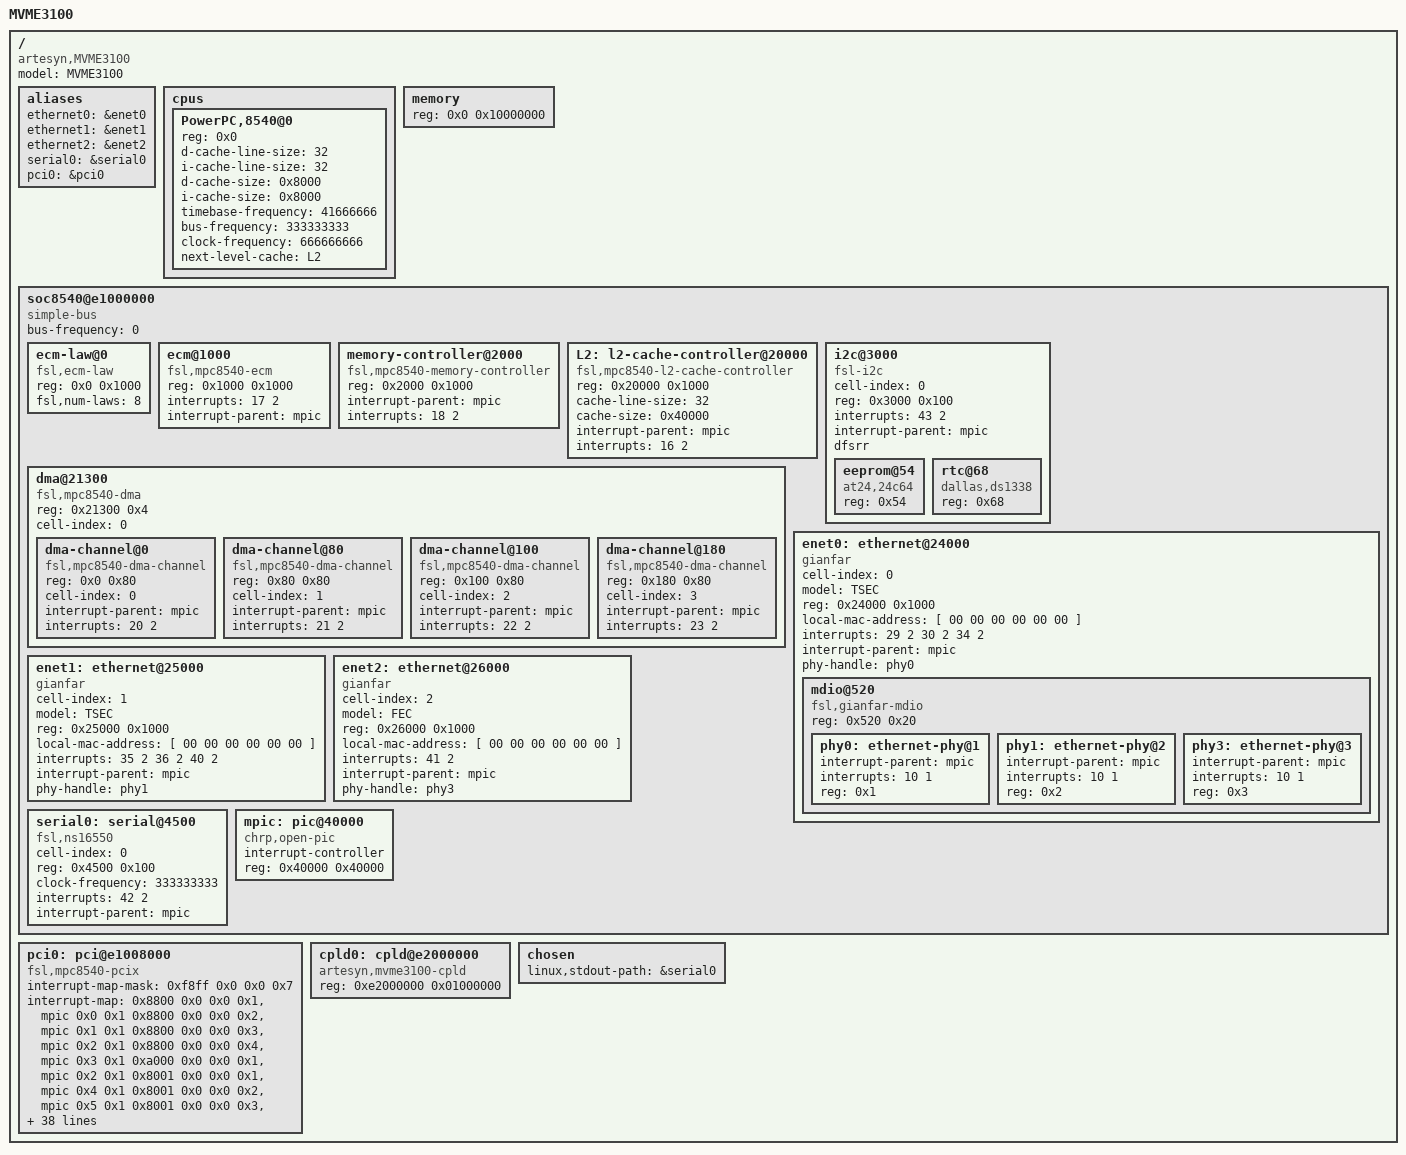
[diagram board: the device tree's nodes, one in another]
/*
 * MVME3100 Device Tree Source
 *
 * Copyright 2017 Michael Davidsaver
 * Copyright 2006, 2008 Freescale Semiconductor Inc.
 *
 * This program is free software; you can redistribute  it and/or modify it
 * under  the terms of  the GNU General  Public License as published by the
 * Free Software Foundation;  either version 2 of the  License, or (at your
 * option) any later version.
 */

/dts-v1/;

/include/ "e500v2_power_isa.dtsi"

/ {
        model = "MVME3100";
        compatible = "artesyn,MVME3100", "MPC85xxADS";
	#address-cells = <1>;
	#size-cells = <1>;

	aliases {
		ethernet0 = &enet0;
		ethernet1 = &enet1;
		ethernet2 = &enet2;
		serial0 = &serial0;
		pci0 = &pci0;
	};

	cpus {
		#address-cells = <1>;
		#size-cells = <0>;

		PowerPC,8540@0 {
			device_type = "cpu";
			reg = <0x0>;
			d-cache-line-size = <32>;	// 32 bytes
			i-cache-line-size = <32>;	// 32 bytes
			d-cache-size = <0x8000>;		// L1, 32K
			i-cache-size = <0x8000>;		// L1, 32K
			timebase-frequency = <41666666>;	//  CCB/8
			bus-frequency = <333333333>;	// CCB
			clock-frequency = <666666666>;	// core for mvme3100-1152
			next-level-cache = <&L2>;
		};
	};

	memory {
		device_type = "memory";
		reg = <0x0 0x10000000>;	// 256M at 0x0
	};

	soc8540@e1000000 {
		#address-cells = <1>;
		#size-cells = <1>;
		device_type = "soc";
		compatible = "simple-bus";
		ranges = <0x0 0xe1000000 0x100000>;
		bus-frequency = <0>;

		ecm-law@0 {
			compatible = "fsl,ecm-law";
			reg = <0x0 0x1000>;
			fsl,num-laws = <8>;
		};

		ecm@1000 {
			compatible = "fsl,mpc8540-ecm", "fsl,ecm";
			reg = <0x1000 0x1000>;
			interrupts = <17 2>;
			interrupt-parent = <&mpic>;
		};

		memory-controller@2000 {
			compatible = "fsl,mpc8540-memory-controller";
			reg = <0x2000 0x1000>;
			interrupt-parent = <&mpic>;
			interrupts = <18 2>;
		};

		L2: l2-cache-controller@20000 {
			compatible = "fsl,mpc8540-l2-cache-controller";
			reg = <0x20000 0x1000>;
			cache-line-size = <32>;	// 32 bytes
			cache-size = <0x40000>;	// L2, 256K
			interrupt-parent = <&mpic>;
			interrupts = <16 2>;
		};

		i2c@3000 {
			#address-cells = <1>;
			#size-cells = <0>;
			cell-index = <0>;
			compatible = "fsl-i2c";
			reg = <0x3000 0x100>;
			interrupts = <43 2>;
			interrupt-parent = <&mpic>;
			dfsrr;

			eeprom@54 {
				compatible = "at24,24c64";
				reg = <0x54>;
			};

                        rtc@68 {
                                compatible = "dallas,ds1338";
                                reg = <0x68>;
                        };
		};

		dma@21300 {
			#address-cells = <1>;
			#size-cells = <1>;
			compatible = "fsl,mpc8540-dma", "fsl,eloplus-dma";
			reg = <0x21300 0x4>;
			ranges = <0x0 0x21100 0x200>;
			cell-index = <0>;
			dma-channel@0 {
				compatible = "fsl,mpc8540-dma-channel",
						"fsl,eloplus-dma-channel";
				reg = <0x0 0x80>;
				cell-index = <0>;
				interrupt-parent = <&mpic>;
				interrupts = <20 2>;
			};
			dma-channel@80 {
				compatible = "fsl,mpc8540-dma-channel",
						"fsl,eloplus-dma-channel";
				reg = <0x80 0x80>;
				cell-index = <1>;
				interrupt-parent = <&mpic>;
				interrupts = <21 2>;
			};
			dma-channel@100 {
				compatible = "fsl,mpc8540-dma-channel",
						"fsl,eloplus-dma-channel";
				reg = <0x100 0x80>;
				cell-index = <2>;
				interrupt-parent = <&mpic>;
				interrupts = <22 2>;
			};
			dma-channel@180 {
				compatible = "fsl,mpc8540-dma-channel",
						"fsl,eloplus-dma-channel";
				reg = <0x180 0x80>;
				cell-index = <3>;
				interrupt-parent = <&mpic>;
				interrupts = <23 2>;
			};
		};

		/* GMII */
		enet0: ethernet@24000 {
			#address-cells = <1>;
			#size-cells = <1>;
			cell-index = <0>;
			device_type = "network";
			model = "TSEC";
			compatible = "gianfar";
			reg = <0x24000 0x1000>;
			ranges = <0x0 0x24000 0x1000>;
			local-mac-address = [ 00 00 00 00 00 00 ];
			interrupts = <29 2 30 2 34 2>;
			interrupt-parent = <&mpic>;
			phy-handle = <&phy0>;

			mdio@520 {
				#address-cells = <1>;
				#size-cells = <0>;
				compatible = "fsl,gianfar-mdio";
				reg = <0x520 0x20>;

				phy0: ethernet-phy@1 {
					interrupt-parent = <&mpic>;
					interrupts = <10 1>;
					reg = <0x1>;
				};
				phy1: ethernet-phy@2 {
					interrupt-parent = <&mpic>;
					interrupts = <10 1>;
					reg = <0x2>;
				};
				phy3: ethernet-phy@3 {
					interrupt-parent = <&mpic>;
					interrupts = <10 1>;
					reg = <0x3>;
				};
			};
		};

		/* GMII */
		enet1: ethernet@25000 {
			#address-cells = <1>;
			#size-cells = <1>;
			cell-index = <1>;
			device_type = "network";
			model = "TSEC";
			compatible = "gianfar";
			reg = <0x25000 0x1000>;
			ranges = <0x0 0x25000 0x1000>;
			local-mac-address = [ 00 00 00 00 00 00 ];
			interrupts = <35 2 36 2 40 2>;
			interrupt-parent = <&mpic>;
			phy-handle = <&phy1>;
		};

		/* TODO: actually a 10/100 FEC interface */
		enet2: ethernet@26000 {
			#address-cells = <1>;
			#size-cells = <1>;
			cell-index = <2>;
			device_type = "network";
			model = "FEC";
			compatible = "gianfar";
			reg = <0x26000 0x1000>;
			ranges = <0x0 0x26000 0x1000>;
			local-mac-address = [ 00 00 00 00 00 00 ];
			interrupts = <41 2>;
			interrupt-parent = <&mpic>;
			phy-handle = <&phy3>;
		};

		serial0: serial@4500 {
			cell-index = <0>;
			device_type = "serial";
			compatible = "fsl,ns16550", "ns16550";
			reg = <0x4500 0x100>; 	// reg base, size
                        clock-frequency = <333333333>;  // CCB
			interrupts = <42 2>;
			interrupt-parent = <&mpic>;
		};

		mpic: pic@40000 {
			interrupt-controller;
			#address-cells = <0>;
			#interrupt-cells = <2>;
			reg = <0x40000 0x40000>;
			compatible = "chrp,open-pic";
			device_type = "open-pic";
		};
	};

	pci0: pci@e1008000 {
		interrupt-map-mask = <0xf8ff 0x0 0x0 0x7>;
		interrupt-map = <

		/* On Host bridge (bus 0) */

		/* IDSEL 17 (TSI148) */
		0x8800 0x0 0x0 0x1 &mpic 0x0 0x1
		0x8800 0x0 0x0 0x2 &mpic 0x1 0x1
		0x8800 0x0 0x0 0x3 &mpic 0x2 0x1
		0x8800 0x0 0x0 0x4 &mpic 0x3 0x1

		/* IDSEL 20 (SATA) */
		0xa000 0x0 0x0 0x1 &mpic 0x2 0x1

		/* behind bridge 0:12.0 (bus 1) */

		/* IDSEL 16 (PMC1 pri) */
		0x8001 0x0 0x0 0x1 &mpic 0x4 0x1
		0x8001 0x0 0x0 0x2 &mpic 0x5 0x1
		0x8001 0x0 0x0 0x3 &mpic 0x6 0x1
		0x8001 0x0 0x0 0x4 &mpic 0x7 0x1

		/* IDSEL 17 (PMC1 sec */
		0x8801 0x0 0x0 0x1 &mpic 0x5 0x1
		0x8801 0x0 0x0 0x2 &mpic 0x6 0x1
		0x8801 0x0 0x0 0x3 &mpic 0x7 0x1
		0x8001 0x0 0x0 0x4 &mpic 0x4 0x1

		/* IDSEL 18 (PMC2 pri) */
		0x9001 0x0 0x0 0x1 &mpic 0x6 0x1
		0x9001 0x0 0x0 0x2 &mpic 0x7 0x1
		0x9001 0x0 0x0 0x3 &mpic 0x4 0x1
		0x9001 0x0 0x0 0x4 &mpic 0x5 0x1

		/* IDSEL 19 (PMC2 sec */
		0x9801 0x0 0x0 0x1 &mpic 0x7 0x1
		0x9801 0x0 0x0 0x2 &mpic 0x4 0x1
		0x9801 0x0 0x0 0x3 &mpic 0x5 0x1
		0x9001 0x0 0x0 0x4 &mpic 0x6 0x1

		/* behind bridge 0:13.0 (bus 2) */

		/* IDSEL 16 (USB) */
		0x8002 0x0 0x0 0x1 &mpic 0x4 0x1
		0x8002 0x0 0x0 0x2 &mpic 0x5 0x1
		0x8002 0x0 0x0 0x3 &mpic 0x6 0x1

		/* IDSEL 18 (PMCSpan slot 1) */
		0x9002 0x0 0x0 0x1 &mpic 0x6 0x1
		0x9002 0x0 0x0 0x2 &mpic 0x7 0x1
		0x9002 0x0 0x0 0x3 &mpic 0x4 0x1
		0x9002 0x0 0x0 0x4 &mpic 0x5 0x1

		/* IDSEL 19 (PMCSpan slot 2) */
		0x9802 0x0 0x0 0x1 &mpic 0x7 0x1
		0x9802 0x0 0x0 0x2 &mpic 0x4 0x1
		0x9802 0x0 0x0 0x3 &mpic 0x5 0x1
		0x9002 0x0 0x0 0x4 &mpic 0x6 0x1

		/* IDSEL 20 (PMCSpan slot 3) */
		0xa002 0x0 0x0 0x1 &mpic 0x4 0x1
		0xa002 0x0 0x0 0x2 &mpic 0x5 0x1
		0xa002 0x0 0x0 0x3 &mpic 0x6 0x1
		0xa002 0x0 0x0 0x4 &mpic 0x7 0x1

		/* IDSEL 21 (PMCSpan slot 4) */
		0xa802 0x0 0x0 0x1 &mpic 0x5 0x1
		0xa802 0x0 0x0 0x2 &mpic 0x6 0x1
		0xa802 0x0 0x0 0x3 &mpic 0x7 0x1
		0xa802 0x0 0x0 0x4 &mpic 0x8 0x1>;

		interrupt-parent = <&mpic>;
		interrupts = <24 2>;
		bus-range = <0 0>;
                ranges = <0x2000000 0x0 0x80000000 0x80000000 0x0 0x40000000
                              0x2000000 0x0 0xc0000000 0xc0000000 0x0 0x20000000
                              0x1000000 0x0 0x0 0xe0000000 0x0 0x1000000>;
		clock-frequency = <66666666>;
		#interrupt-cells = <1>;
		#size-cells = <2>;
		#address-cells = <3>;
		reg = <0xe1008000 0x1000>;
		compatible = "fsl,mpc8540-pcix", "fsl,mpc8540-pci";
		device_type = "pci";
	};

        cpld0: cpld@e2000000 {
                reg = <0xe2000000 0x01000000>;
                compatible = "artesyn,mvme3100-cpld";
        };

	chosen {
		linux,stdout-path = &serial0;
	};
};
